# cslr_venc_001 register map
Vendor: Texas Instruments
Peripheral module from a debugger description file.
Registers are 32-bit, access per field, reset 0x0 unless marked. A register's access mark holds for its fields unless they carry their own. Offsets are as the file gives them; lines under a group give offsets from that group; [hi:lo] are bit positions; {n}, {i} and the like mark numbered series; 'fields as' and 'values as' point back to an identical list; <NAME> marks a mode.

## VENC — VPBE Video Encoder / Digital LCD Subsystem (spec version: 1.00.w.02b)
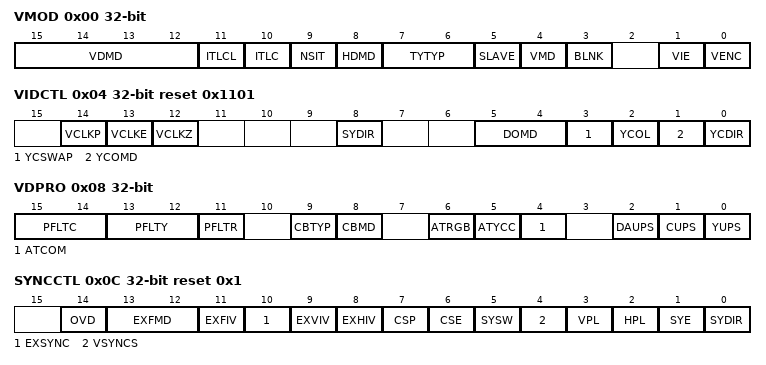
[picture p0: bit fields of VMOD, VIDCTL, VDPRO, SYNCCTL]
0x00 VMOD — Video Mode
  [15:12] VDMD rw — Digital video output mode
    0=YCBCR_16BIT (YCbCr parallel 16 bit); 1=YCBCR_8BIT (YCbCr serial 8 bit); 2=RGB666_18BIT (RGB666 parallel 18 bit); 3=RGB8_8BIT (RGB8 serial 8 bit); 4=EPSON; 5=CASIO; 6=UDISP_QVGA (uDISP (QVGA uDisplay)); 7=STN_LCD (STN (STN-LCD))
  [11] ITLCL rw — Non-interlace line number select Effective in standard SDTV non-interlace mode (VMD=0, HDMD=0, ITLC=1).
    0=262NTSC_312PAL (262 line (NTSC) / 312 line (PAL)); 1=263NTSC_313PAL (263 line (NTSC) / 313 line (PAL))
  [10] ITLC rw — Interlaced Scan Mode Enable Effective in standard SDTV mode (VMD=0, HDMD=0)
    0=INTERLACE; 1=NON_INTERLACE
  [9] NSIT rw — Nonstandard interlace mode Effective in non-standard mode (VMD=1).
    0=PROGRESSIVE; 1=INTERLACE
  [8] HDMD rw — HDTV mode Effective in standard mode (VMD=0).
    0=SDTV; 1=HDTV
  [7:6] TYTYP rw — TV Format Type Select Effective in standard mode (VMD=0). SDTV mode (HDMD=0) HDTV mode (HDMD=1)
    0=SDTV_NTSC (SDTV Mode - NTSC); 1=SDTV_PAL (SDTV Mode - PAL); 2=SDTV_RESERVEDS1 (SDTV Mode - reservedS1); 3=SDTV_RESERVEDS2 (SDTV Mode - reservedS2); 0=HDTV_525P (HDTV Mode - 525P); 1=HDTV_625P (HDTV Mode - 625P); 2=HDTV_RESERVEDH1 (HDTV Mode - reservedH1); 3=HDTV_RESERVEDH2 (HDTV Mode - reservedH2)
  [5] SLAVE rw — Master-slave select
    0=MASTERMODE; 1=SLAVEMODE
  [4] VMD rw — Video timing
    0=NTSC_PALTIMING; 1=NOTNTSC_PALTIMING
  [3] BLNK rw — Blanking enable Sync signal and color burst are still output
    0=NORMAL; 1=FORCEBLANKING
  [1] VIE rw — Composite Analog Output Enable
    0=FIXED_L_LEVEL_OUT (Fixed L level output); 1=NORMAL_COMPOSITE_OUT (Normal composite output)
  [0] VENC rw — Video Encoder Enable
    0=DISABLE; 1=ENABLE
0x04 VIDCTL reset 0x1101 — Video interface I/O control
  [14] VCLKP rw — VCLK output polarity
    0=NON_INVERSE; 1=INVERSE
  [13] VCLKE rw — VCLK output enable Note: Setting 1 outputs DCLK from VCLK pin. When 0 VCLKP setting is still available
    0=OFF; 1=ON
  [12] VCLKZ rw — VCLK pin output enable
    0=OUTPUT; 1=HIGHIMPEDENCE
  [8] SYDIR rw — Horizontal / Vertical Sync pin I/O control Set to 1 when external syncs are input Default is 1(input)
    0=OUTPUT; 1=INPUT
  [5:4] DOMD rw — Digital data output mode
    0=NORMAL_OUT (Normal output); 1=INVERSE_OUT (Inverse output); 2=L_LEVEL_OUT (L level output); 3=H_LEVEL_OUT (H level output)
  [3] YCSWAP rw — Swaps YOUT/COUT pins Interchanges the output data of YOUT and COUT
    0=NORMAL (Normal output); 1=SWAP_YC (Interchange YOUT and COUT)
  [2] YCOL rw — YOUT / COUT pin output level Setting DC out option will output the value in the YCOLVL register on YOUT/COUT pins. Effective only when YOUT/COUT pin is set as output (YCDIR=0).
    0=NORMAL_OUT (Normal output); 1=DCLEVEL_OUT (DC level output)
  [1] YCOMD rw — YOUT / COUT pin output mode Setting DV out will output the digital video output generated in video encoder on the YOUT/COUT pins. Setting Through Mode directly outputs the data from the YIN/CIN pins on the YOUT/COUT pins.
    0=DIGITAL_VIDEO_OUT (Digital video output); 1=YC_INPUT_PASSTHRU (YIN / CIN input through)
  [0] YCDIR rw — YOUT / COUT pin direction Note: YOUT/COUT pin is used as YC data input pin for CCDC. Set '0' for digital video output In Input Mode, YOUT/COUT pins are used as YC data input pins for CCDC. Set to Outptu Mode for digital video output. When UDISP digital video output mode is selected (VOMD=6), COUT[1:0] pins are always set to input.
    0=OUTPUT; 1=INPUT
0x08 VDPRO — Video data processing
  [15:14] PFLTC rw — C Prefilter select Note: When PFLTR and PFLTC are '1', use PFLTY to 1 to adjust delay between Y and C. When other combinations are selected, the delay is adjusted automatically on hardware.
    0=NOFILTER; 1=1_1; 2=1_2_1
  [13:12] PFLTY rw — Y Prefilter select Note: When PFLTR and PFLTY are '1', use PFLTC to 1 to adjust delay between Y and C. When other combinations are selected, the delay is adjusted automatically on hardware.
    0=NOFILTER; 1=1_1; 2=1_2_1
  [11] PFLTR rw — Prefilter sampling frequency
    0=ENCCLOCK_2; 1=ENCCLOCK
  [9] CBTYP rw — Color Bar Type
    0=75PCT; 1=100PCT
  [8] CBMD rw — Color bar mode
    0=NORMAL (Normal output); 1=COLORBAR (Color bar output)
  [6] ATRGB rw — Input video Attenuation control for RGB
    0=NOATTENUATION; 1=REC601_LVL (0-255 => REC601 specified level)
  [5] ATYCC rw — Input video Attenuation control for YCbCr
    values as ATRGB
  [4] ATCOM rw — Input video Attenuation control for composite
    values as ATRGB
  [2] DAUPS rw — DAC x2 up-sampling enable
    0=OFF; 1=ON
  [1] CUPS rw — C signal up-sampling enable
    0=OFF; 1=ON
  [0] YUPS rw — Y signal up-sampling enable
    0=OFF; 1=ON
0x0C SYNCCTL reset 0x1 — Sync control
  [14] OVD rw — OSD vsync delay
    0=NODELAY; 1=DELAY (Delay 0.5H)
  [13:12] EXFMD rw — External field detection mode Effective in slave operation (SLAVE=1).
    0=LATCH_EXT_FLD_AT_VDHIGH (latch ext. field at external VD rising edge); 1=USE_RAW_EXT_FLD (use raw external field); 2=USE_EXT_VSYNC_AS_FLDID (use external vsync as field ID); 3=DET_EXT_VSYNC_PH (detect external vsync phase)
  [11] EXFIV rw — External field input inversion Effective in slave operation (SLAVE=1). External field
    0=NON_INVERSE; 1=INVERSE
  [10] EXSYNC rw — External sync select
    0=HSYNC_VSYNCPIN; 1=CCDSYNCSIGNAL
  [9] EXVIV rw — External vertical sync input polarity
    0=ACTIVEH; 1=ACTIVEL
  [8] EXHIV rw — External horizontal sync input polarity
    0=ACTIVEH; 1=ACTIVEL
  [7] CSP rw — Composite signal output polarity Note: Specifies composite signal output polarity from COUT3 pin in YCC8 or RGB8 mode
    0=ACTIVEH; 1=ACTIVEL
  [6] CSE rw — Composite signal output enable Note: Specifies composite signal output polarity from COUT3 pin in YCC8 or RGB8 mode
    0=OFF; 1=ON
  [5] SYSW rw — Output sync select Note: Applicable to Standard mode only Setting '1' in standard mode outputs the pulse width processed by the SYNCPLS register as output sync signal.
    0=NORMAL; 1=SYNC_PW_PROC (Sync pulse width processing mode)
  [4] VSYNCS rw — Vertical sync output signal
    0=VSYNC (Vertical sync signal); 1=COMPOSITE_SYNC (composite sync signal)
  [3] VPL rw — Vertical sync output polarity
    0=ACTIVEH; 1=ACTIVEL
  [2] HPL rw — Horizontal sync output polarity
    0=ACTIVEH; 1=ACTIVEL
  [1] SYE rw — Vertical sync output enable The output comes to ON when this is set to 1, and the signal selected by the VSSW is output from VSYNC pin. Setting 0 outputs inactive level determined by VPL.
    0=OFF; 1=ON
  [0] SYDIR rw — Horizontal sync output enable The output comes to ON when this is set to 1, and the signal selected by the VSSW is output from HSYNC pin. Setting 0 outputs inactive level determined by HPL.
    0=OFF; 1=ON
0x10 HSPLS — Horizontal Sync pulse width
  [12:0] HSPLS rw — Horizontal sync pulse width (no of ENC clocks) Note: Effective in non-standard mode or sync processing mode (SYSW = 1)
0x14 VSPLS — Vertical Sync pulse width
  [12:0] VSPLS rw — Vertical sync pulse width (no of ENC clocks) Note: Effective in non-standard mode or sync processing mode (SYSW = 1)
0x18 HINT — Horizontal interval
  [12:0] HINT rw — Horizontal interval (no of ENC clocks) Note: Effective in non-standard mode, If OSD clock is (ENC clock / 2), Specify even values. Interval is HINT+1
0x1C HSTART — Horizontal valid data start position
  [12:0] HSTART rw — Horizontal valid data start position Note: Specify number of ENC clocks from start of horizontal sync. LCD_OE is asserted at the position specified here and the data output starts.
0x20 HVALID — Horizontal data valid range
  [12:0] HVALID rw — Horizontal data valid range Note: specify number of ENC clocks. LCD_OE is asserted during the period specified here and valid data is output. The data outside of valid range is output in L.
0x24 VINT — Vertical interval
  [12:0] VINT rw — Vertical interval (no of lines) Note: Effective in non-standard mode The interval is represented by VINT+1
0x28 VSTART — Vertical valid data start position
  [12:0] VSTART rw — Vertical valid data start position Note: Specify number of lines
0x2C VVALID — Vertical data valid range
  [12:0] VVALID rw — Vertical data valid range Note: specify number of lines
0x30 HSDLY — Horizontal sync delay
  [12:0] HSDLY rw — Output delay of horizontal sync signal Note: This will delay the HSYNC signal by ENC clock
0x34 VSDLY — Vertical sync delay
  [12:0] VSDLY rw — Output delay of vertical sync signal Note: This will delay the VSYNC signal by ENC clock
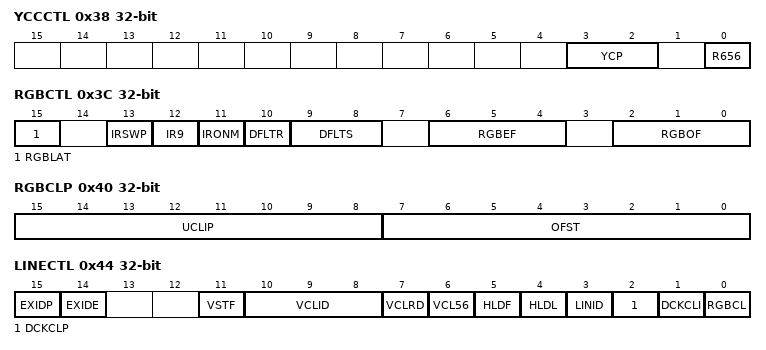
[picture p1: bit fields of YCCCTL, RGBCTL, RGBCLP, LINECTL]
0x38 YCCCTL — YCbCr control
  [3:2] YCP rw — YC output order Based on YCC mode
    0=YCC16_CBCR (YCC16 mode - CbCr); 1=yCC16_CRCB (YCC16 mode - CrCb); 0=YCC8_CB_Y_CR_Y (YCC8 mode - Cb-Y-Cr-Y); 1=YCC8_Y_CR_Y_CB (YCC8 mode - Y-Cr-Y-Cb); 2=YCC8_CR_Y_CB_Y (YCC8 mode - Cr-Y-Cb-Y); 3=YCC8_Y_CB_Y_CR (YCC8 mode - Y-Cb-Y-Cr)
  [0] R656 rw — REC656 mode This is ITU-R BT.656 format and is effective when the OSD clock runs at ENC clock/2.
    0=NORMAL; 1=REC656 (REC656 mode)
0x3C RGBCTL access not given (reset mask 0xFFFFFFF8) — RGB control
  [15] RGBLAT rw — RGB latch setting Set 1 to latch and output the data input in serial RGB output. This is set when data with the same pixel are output serially.
    0=NORMALOUTPUT; 1=LATCHMODE
  [13] IRSWP rw — Swap order of data output in IronMan mode Effective only IRONM=1
    0=NORMAL; 1=IR_SWAP (Data swap)
  [12] IR9 rw — IronMan 9bit mode Effective only IRONM=1. When 1, 24-bit RGB data (upper 6-bits of each color) is serially output on 9-bit data bus. The output format is the first is R[7:2] and G[7:5] and the second is G[4:2] and B[7:2]. This order can be swapped by IRSWP register.
    0=IR_8BIT (8-bit); 1=IR_9-BIT (9-bit)
  [11] IRONM rw — Iron-man type RGB output Effective in SRGB mode
    0=NORMAL; 1=IRONMAN (Iron-man type)
  [10] DFLTR rw — RGB LPF sampling frequency Effective in all digital output modes with RGB output Note: Effective in all digital modes with RGB output
    0=ENCCLOCK_2; 1=ENCCLOCK
  [9:8] DFLTS rw — RGB LPF select Note: Effective in all digital modes with RGB output
    0=NOFILTER; 1=1_2_1; 2=1_2_4_2_1
  [6:4] RGBEF rw — RGB output order (Line Id = 1) Note: Effective in RGB8, EPSON and CASIO modes. The line ID at RGBCL=1 represents the culling line ID set in the CULLLINE register. At RGBCL=0, it represents normal line ID.
    0=R0_G1_B2; 1=R0_B1_G2; 2=G0_R1_B2; 3=G0_B1_R2; 4=B0_R1_G2; 5=B0_G1_R2
  [2:0] RGBOF — RGB output order (Line Id = 0) Note: Effective in RGB8, EPSON and CASIO modes. The line ID at RGBCL=1 represents the culling line ID set in the CULLLINE register. At RGBCL=0, it represents normal line ID.
    values as RGBEF
0x40 RGBCLP — RGB level clipping
  [15:8] UCLIP rw — Upper clip level for RGB output Note: Effective in all digital output modes with RGB output. Clipping is done following offset addition
  [7:0] OFST rw — Offset level for RGB output Note: Effective in all digital output modes with RGB output. Offset specified here can be added to RGB converted from YCbCr
0x44 LINECTL — Line Id control
  [15] EXIDP rw — External Line Id signal polarity Effective at EXIDE=1
    0=NON_INVERSE; 1=INVERSE
  [14] EXIDE rw — External Line Id signal input mode Set External to perform the line control using external line ID signal, which can be input from a GIO. Otehrwise, the line ID is generated internally.
    0=INTERNALIDLINE; 1=EXTERNALIDLINE
  [11] VSTF rw — Vertical data valid start position field mode When 1, different start line can be specified for vertical data valid start position by VSTARTA register.
    0=NORMALMODE; 1=FIELDMODE
  [10:8] VCLID rw — Vertical Culling line position Specifies which line will be culled of every six lines. No culling will be applied when VCLID is greater than 5. This bit is effective when VCL56=1.
  [7] VCLRD rw — Vertical Culling counter reset mode When 0, the counter for vertical culling is reset to zero at vertical sync. When 1, it is reset to a random value at vertical sync. Effective when VCL56=1.
    0=RESET_0 (Reset to 0); 1=RESET_RAND (Reset to Random value)
  [6] VCL56 rw — Digital output vertical culling Enabling discards one line of video output every six lines. This can be used to output NTSC valid lines with PAL timing.
    0=NOCULLING; 1=5_6CULLING
  [5] HLDF rw — Digital output Field Hold Note: Effective in non-standard mode. Enabling suspends the video output when current field output is completed. Reading the data from OSD is suspended during this period and the output of sync signal and video data ar
    0=NORMAL; 1=OUTPUTHOLD
  [4] HLDL rw — Digital output Line Hold Note: Effective in non-standard mode. Enabling suspends the video output when current line output is completed. Reading the data from OSD is suspended during this period and the output of sync signal and video data are al
    0=NORMAL; 1=OUTPUTHOLD
  [3] LINID rw — Start line Id control in even field
    0=LINEID_0; 1=LINEID_1
  [2] DCKCLP rw — DCLK pattern switching by culling line Id When this is enabled, the DCLK pattern can be switched according to the culling line ID set by the CULLLINE register. The DCLK pattern on each line is specified by the DCLKPTN and DCLKPTNA registers.
    0=OFF; 1=ON
  [1] DCKCLI rw — DCLK polarity inversion by culling line Id When this is disabled, the DCLK polarity is fixed anytime as specified by the VCLKP register. Enabling inverts this polarity according to the culling line ID set by the CULLLINE register.
    0=OFF; 1=ON
  [0] RGBCL rw — RGB output order switching by culling line Id Disabling switches RGB output order every line. Enabling switches this order according to the XORed signal of the line ID and the culling line ID set by the CULLLINE register. The output order on each
    0=OFF; 1=ON
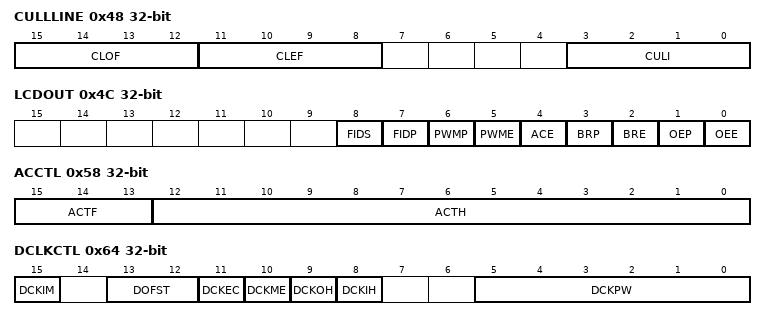
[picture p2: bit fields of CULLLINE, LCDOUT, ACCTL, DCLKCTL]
0x48 CULLLINE access not given — Culling line control
  [15:12] CLOF rw — Culling line Id toggle position (Odd field)
  [11:8] CLEF rw — Culling line Id toggle position (Even field)
  [3:0] CULI rw — Culling line Id inversion interval
0x4C LCDOUT — LCD output signal control
  [8] FIDS rw — GIO39 output signal select Note: Select GIO29 signal using FSEL2[11:10] = 01
    0=FIELDID; 1=LCD_OE
  [7] FIDP rw — Field Id output polarity
    0=NON_INVERSE; 1=INVERSE
  [6] PWMP rw — PWM output pulse polarity
    0=ACTIVEH; 1=ACTIVEL
  [5] PWME rw — PWM output control
    0=OFF; 1=ON
  [4] ACE rw — LCD_AC output control
    0=OFF; 1=ON
  [3] BRP rw — Bright output polarity
    0=NON_INVERSE; 1=INVERSE
  [2] BRE rw — Bright output control
    0=OFF; 1=ON
  [1] OEP rw — LCD_OE output polarity
    0=ACTIVEH; 1=ACTIVEL
  [0] OEE rw — LCD_OE output control
    0=OFF; 1=ON
0x50 BRTS — Brightness start position signal control
  [12:0] BRTS rw — Bright pulse start position Specify the number of ENC cycles from HSYNC signal.
0x54 BRTW — Brightness width signal control
  [12:0] BRTW rw — Bright pulse width Specify the number of ENC cycles.
0x58 ACCTL — LCD_AC signal control
  [15:13] ACTF rw — LCD_AC toggle interval Note: LCD_AC is toggled every field specified here
  [12:0] ACTH rw — LCD_AC toggle horizontal position Note: LCD_AC is toggled by the number of ENC clocks from the rising edge of horizontal sync signal
0x5C PWMP — PWM start position signal control
  [12:0] PWMP rw — PWM output period Specify the number of ENC clocks. Period is PWMP + 1
0x60 PWMW — PWM width signal control
  [12:0] PWMW rw — PWM output pulse width Specify the H pulse width by ENC clock. Setting '0' makes PWM output L level always, Setting bigger value than PWMP sets to H level always,
0x64 DCLKCTL — DCLK control
  [15] DCKIM rw — DCLK Internal Mode When enabled, a different pattern can be specified for internal DCLK from output DCLK. In this mode, DCLKPTN0A-PCLKPTN3A and DCLKHSTTA are used to specify the internal DCLK pattern and its pattern valid bit width respectively. Th
    0=OFF; 1=ON
  [13:12] DOFST rw — DCLK output offset To adjust the DCLK delay output from VCLK pin by ENC clock. When DCLK output is configured as ENC clock gating with DCKEC=1 and DCKOH=0, these bits have no meaning.
    0=ZERO (0); 1=MINUS_HALF (-0.5); 2=PLUS_HALF (0.5); 3=PLUS_ONE (1)
  [11] DCKEC rw — DCLK Pattern mode When 0, the specified value in DCLKPTN (or DCLKPTNA) register becomes the clock level of DCLK. When 1, DCLKPTN works as the clock enable for ENC clock.
    0=LEVEL; 1=ENABLE
  [10] DCKME rw — DCLK mask control Masks are specified by the DCLKHSTT, DCLKHVLD, DCLKVSTT and DCLKVVLD registers. Enabling represents the mask is ON and outputs the clock in specified valid area. Disabling represents the mask is OFF and outputs directly the DCLK
    0=OFF; 1=ON
  [9] DCKOH rw — DCLK output divide Enabling divides the clock by two and outputs it from VCLK pin. RGB data is output by the rising of internal DCLK and only divided clock output is output. Thus, this can be used to connect to the LCD that captures the data usin
    0=DIV_BY_1 (Divide by 1); 1=DIV_BY_2 (Divide by 2)
  [8] DCKIH rw — Internal DCLK output divide Enabling divides internal DCLK clock by two. When the clock output is divided by 1 (DCKOH=0), two clocks can be output per one data. Thus, this can be used to connect to the LCD that requires double clock frequency of d
    0=DIV_BY_1 (Divide by 1); 1=DIV_BY_2 (Divide by 2)
  [5:0] DCKPW rw — DCLK pattern valid bit width Note: Set the width of valid bits aming 64 bits in the DCLKPTN0-3 registers
{0x68+4i} DCLKPTN{i} (i=0..3) — DCLK pattern {i}
  [15:0] DCPTN{i} rw — DCLK pattern The specified bit pattern is output in resolution of ENC clock units
{0x78+4i} DCLKPTN{i}A (i=0..3) — DCLK auxiliary pattern {i}
  [15:0] DCPTN{i}A rw — DCLK pattern (auxiliary) The specified bit pattern is output in resolution of ENC clock units
0x88 DCLKHS — Horizontal DCLK mask start
  [12:0] DCHS rw — Horizontal DCLK mask start position This is specified in number of ENC clocks from start of the horizontal sync signal
0x8C DCLKHSA — Horizontal auxiliary DCLK mask start
  [12:0] DCHS rw — Horizontal DCLK (auxiliary) mask start position This is specified in number of ENC clocks from start of the horizontal sync signal
0x90 DCLKHR — Horizontal DCLK mask range
  [12:0] DCHR rw — Horizontal DCLK mask range This is specified in ENC clocks
0x94 DCLKVS — Vertical DCLK mask start
  [12:0] DCVS rw — DCLK vertival mask start position This is specified in lines from vertical sync signal
0x98 DCLKVR — Vertical DCLK mask range
  [12:0] DCVR rw — DCLK vertical mask range This is specified in number of lines
0x9C ATR0 — Video Attribute Data #0
  [7:0] ATR0 rw — Video attribute data register 0 NTSC - Set the WORD0 data. - Bit7-6 is unused, - Bit5-3 is WORD0-B, - Bit2-0 is WORD0-A PAL - not used
0xA0 ATR1 — Video Attribute Data #1
  [7:0] ATR1 rw — Video attribute data register 1 NTSC - Set the WORD1 and WORD2 data - Bit7-4 is WORD2, - Bit3-0 is WORD1 PAL - Set the GROUP1 and GROUP2 data. - Bit7-4 is GROUP2, - Bit3-0 is GROUP1
0xA4 ATR2 — Video Attribute Data #2
  [7:0] ATR2 rw — Video attribute data register 2 NTSC - Set CRC data and enable attribute insertion. - Bit7 is ATR_EN, - Bit6 is unused, - Bit5-0 is CRC PAL - Set GROUP3 and GROU4 data and enable attribute insertion. - Bit7 is ATR_EN, - Bit6 is ununsed, - Bit5-3 is GROUP4 and - Bit2-0 is GROUP3 ATR_EN: Attribute data insertion enable 0: No insertion 1: Insertion
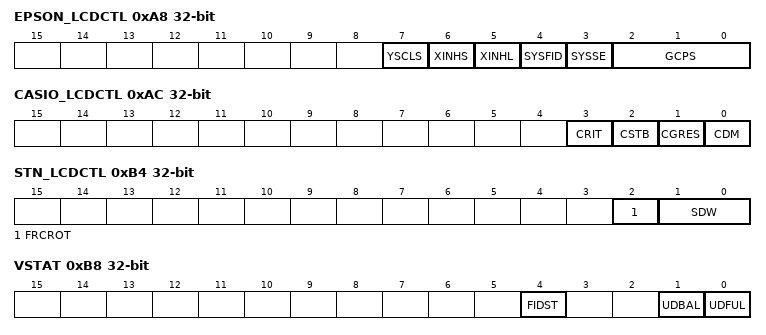
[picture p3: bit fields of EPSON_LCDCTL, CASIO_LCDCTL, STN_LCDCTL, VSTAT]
0xA8 EPSON_LCDCTL — EPSON LCD Control
  [7] YSCLS rw — Low pulse number of YSCL
    0=1PULSE (one pulse (1/2 reset drive)); 1=2PULSES (two pulses (1/2 select drive))
  [6] XINHS rw — XINH Signal select
    0=DCOUTPUT; 1=TGCONTROLLED
  [5] XINHL rw — XINH DC level
    0=LLEVELOUT (L level output); 1=HLEVELOUT (H level output)
  [4] SYSFID rw — SYS function applied field ID select
  [3] SYSSE rw — SYS function enable Note: setting '1 resets the vertical counter one line earlier in the field selected by SYSFID
    0=OFF; 1=ON
  [2:0] GCPS rw — GCP pattern select Note: When RAM is used, data written in RAM address 0-63 is shifter out by one bit from MSB to LSB and output as GCP pulse
    {v}=ROM_TYPE{v} (v=0..3); 4=RAM
0xAC CASIO_LCDCTL — CASIO LCD Control
  [3] CRIT rw — RIT port control Note: Setting is enabled at the rising edge of horizontal sync signal
    0=LLEVELOUT (L level output); 1=HLEVELOUT (H level output)
  [2] CSTB rw — STBYB port control Note: CP output is fixed at H level when 0
    0=LLEVELOUT (L level output); 1=HLEVELOUT (H level output)
  [1] CGRES rw — GRES port control
    0=NORMAL; 1=FIXEDLLEVEL
  [0] CDM rw — Display mode
    0=NORMAL; 1=VERTICALREVERSEMODE
0xB0 UDISP_LCDCTL — uDisplay LCD control
  [7:0] FSW rw — Frame start pulse width This is Specified in ENC clocks
0xB4 STN_LCDCTL — STN LCD control
  [2] FRCROT rw — FRC table rotation enable When enabled, the FRC table for each color is automatically rotated when each pixel data is latched. This can be useful to equalize dot blinking pattern.
    0=DISABLE; 1=ENABLE
  [1:0] SDW rw — STN-LCD data bus width
    0=8BITS; 1=4BITS; 2=12BITS
0xB8 VSTAT — Video status
  [4] FIDST rw — Field ID monitor
  [1] UDBAL rw — uDisplay 'Balance signal' monitor
  [0] UDFUL rw — uDisplay 'Full' signal monitor
0xBC RAMADR — GCP/FRC table RAM address
  [5:0] RAMADR rw — GCP/FRC table RAM address.
0xC0 RAMPORT — GCP/FRC table RAM data port
  [15:0] RAMPORT rw — RAM data port Note: While reading, the data in the address specified in the RAMADR register can be read. While writing, the data is written to the address specified in the RAMADR register. The RAMADR is automatically incremented every access to the RAMP register in both write and read cases.
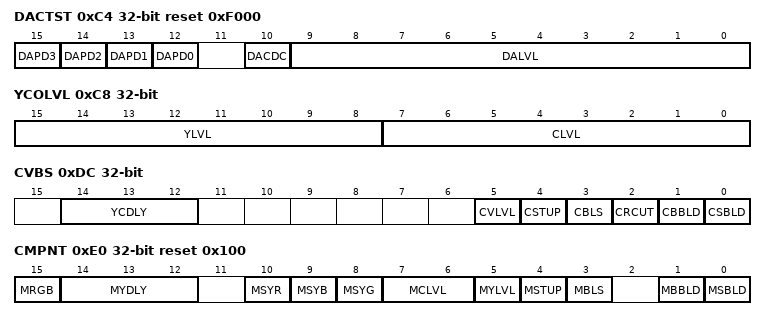
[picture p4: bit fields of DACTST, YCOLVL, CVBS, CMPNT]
0xC4 DACTST reset 0xF000 — DAC Test
  [n+12] DAPD{n} rw (n=0..3) — DAC{n} power-down
    0=NORMAL (Normal mode); 1=PWRDN (Power-down mode)
  [10] DACDC rw — DAC DC output mode Note: Enabling converts the value written in the DALVL register to DAC and directly outputs from DAOUT
    0=NORMAL; 1=DCOUT (DC output mode)
  [9:0] DALVL rw — DC level control
0xC8 YCOLVL — YOUT and COUT levels
  [15:8] YLVL rw — YOUT DC level
  [7:0] CLVL rw — COUT DC level
0xCC SCPROG reset 0x132 — Sub-carrier programming
  [9:0] SCSD rw — Sub-carrier initial phase value Phase in degrees specified by SCSD/1024*360
{0xCC+4i} RSV{i} ro (i=1..3) — Reserved
0xDC CVBS — Composite Mode
  [14:12] YCDLY rw — Delay adjsutment of Y signal in composite signal Note: The value represented is 2's complement
    0=0; 1=PLUS_1 (1); 2=PLUS_2 (2); 3=PLUS_3 (3); 4=MINUS_4 (-4); 5=MINUS_3 (-3); 6=MINUS_2 (-2); 7=MINUS_1 (-1)
  [5] CVLVL rw — Composite video level (sync/white)
    0=286MV_714MV; 1=300MV_700MV
  [4] CSTUP rw — Setup level at NTSC output
    0=0_PCT; 1=7P5_PCT (7.5%)
  [3] CBLS rw — Blanking shape disable
    0=ENABLE; 1=DISABLE
  [2] CRCUT rw — Chroma signal low pass filter select
    0=1P5MHZ_CUT0FF (1.5 MHz cut-0ff); 1=3MHZ_CUTOFF
  [1] CBBLD rw — Blanking build up time for composite output
    0=140US; 1=300US
  [0] CSBLD rw — Sync build up time for composite output
    0=140US; 1=200US
0xE0 CMPNT reset 0x100 — Component Mode
  [15] MRGB rw — RGB Mode select for component output
    0=YPBPR; 1=RGB
  [14:12] MYDLY rw — Delay adjsutment of Y signal in component mode Note: The value represented is 2's complement
    values as CVBS.YCDLY
  [10] MSYR rw — Sync on Pr (or R)
    0=NOSYNC; 1=SYNCON
  [9] MSYB rw — Sync on Pb (or B)
    0=NOSYNC; 1=SYNCON
  [8] MSYG rw — Sync on Y (or G)
    0=NOSYNC; 1=SYNCON
  [7:6] MCLVL rw — Chroma level for component YPbPr
    0=350MV_SMPTEN10; 1=467MV_BETACAM; 2=324MV_MII
  [5] MYLVL rw — Luma level (sync/white) for component YPbPr
    0=286MV_714MV; 1=300MV_700MV
  [4] MSTUP rw — Setup for component YPbPr
    0=0_PCT; 1=7P5_PCT (7.5%)
  [3] MBLS rw — Blanking shape disable When 1, blanking shaping feature is disabled.
    0=ENABLE; 1=DISABLE
  [1] MBBLD rw — Blanking build up time for component output (interlace)
    0=140US; 1=300US; 0=70US; 1=150US
  [0] MSBLD rw — Sync build up time for component output (interlace) (interlace)
    0=140US; 1=200US; 0=70US; 1=100US
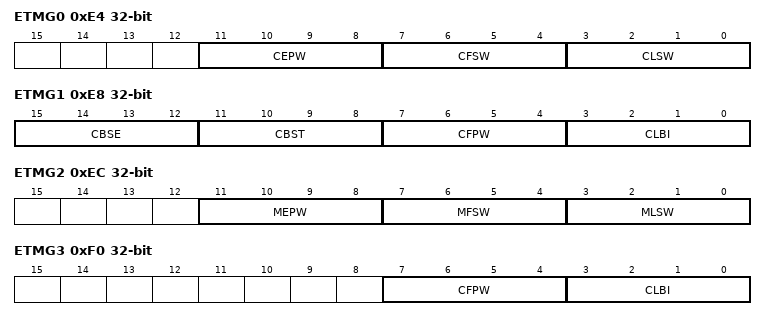
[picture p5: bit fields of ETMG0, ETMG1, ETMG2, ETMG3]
0xE4 ETMG0 — CVBS timing control 0
  [11:8] CEPW rw — Equalizing pulse width offset for composite output This is set by ENC clock. This register is represented as signed-integer (2's complement).
  [7:4] CFSW rw — Field sync pulse width offset for composite output This is set by ENC clock. This register is represented as signed-integer (2's complement).
  [3:0] CLSW rw — Line sync pulse width offset for composite output This is set by ENC clock. This register is represented as signed-integer (2's complement).
0xE8 ETMG1 — CVBS timing control 1
  [15:12] CBSE rw — Burst end position offset for composite output This is set by ENC clock. This register is represented as signed-integer (2's complement).
  [11:8] CBST rw — Burst start position offset for composite output This is set by ENC clock. This register is represented as signed-integer (2's complement).
  [7:4] CFPW rw — Front porch position offset for composite output This is set by ENC clock. This register is represented as signed-integer (2's complement).
  [3:0] CLBI rw — Line blanking end position offset for composite output This is set by ENC clock. This register is represented as signed-integer (2's complement).
0xEC ETMG2 — Component timing control 0
  [11:8] MEPW rw — Equalizing pulse width offset for component output This is set by ENC clock. This register is represented as signed-integer (2's complement).
  [7:4] MFSW rw — Field sync pulse width offset for component output This is set by ENC clock. This register is represented as signed-integer (2's complement).
  [3:0] MLSW rw — Line sync pulse width offset for component output This is set by ENC clock. This register is represented as signed-integer (2's complement).
0xF0 ETMG3 — Component timing control 1
  [7:4] CFPW rw — Front porch position offset for component output This is set by ENC clock. This register is represented as signed-integer (2's complement).
  [3:0] CLBI rw — Line blanking end position offset for component output This is set by ENC clock. This register is represented as signed-integer (2's complement).
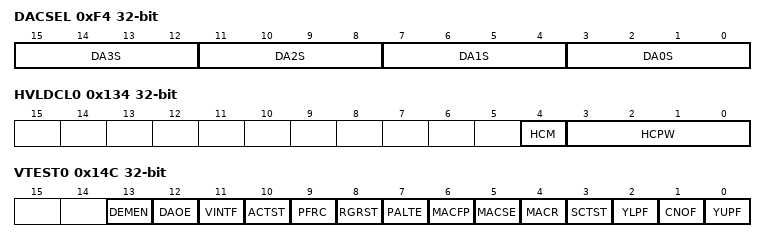
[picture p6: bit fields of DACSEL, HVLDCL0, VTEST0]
0xF4 DACSEL access not given (reset mask 0xFFFFFF00) — DAC output select
  [all] fields
    0=CVBS; 1=SVIDEO_Y; 2=SVIDEO_C; 3=Y_G; 4=PB_B; 5=PR_R
  [15:12] DA3S rw — DAC3 output select
  [11:8] DA2S rw — DAC2 output select
  [7:4] DA1S — DAC1 output select
  [3:0] DA0S — DAC0 output select
0xF8 RSV4 ro — reserved
  [31:0] RSV4 — Reserved
0xFC RSV5 ro — reserved
  [31:0] RSV5 — Reserved
0x100 ARGBX0 reset 0x200 — Analog RGB Matrix 0
  [10:0] AGY rw — YCbCr->RGB matrix coefficient GY for analog RGB out Equation: | R | | GY 0 RV | | Y-16 | | G | = 1/512 | GY -GU -GV | | Cb-128 | | B | | GY BU 0 | | Cr-128 | Default: | R | | 512 0 702 | | Y-16 | | G | = 1/512 | 512 -172 -357 | | Cb-128 | | B | | 512 887 0 | | Cr-128 |
0x104 ARGBX1 reset 0x2BE — Analog RGB Matrix 1
  [10:0] ARV rw — YCbCr->RGB matrix coefficient RV for analog RGB out Equation: | R | | GY 0 RV | | Y-16 | | G | = 1/512 | GY -GU -GV | | Cb-128 | | B | | GY BU 0 | | Cr-128 | Default: | R | | 512 0 702 | | Y-16 | | G | = 1/512 | 512 -172 -357 | | Cb-128 | | B | | 512 887 0 | | Cr-128 |
0x108 ARGBX2 reset 0xAC — Analog RGB Matrix 2
  [10:0] AGU rw — YCbCr->RGB matrix coefficient GU for analog RGB out Equation: | R | | GY 0 RV | | Y-16 | | G | = 1/512 | GY -GU -GV | | Cb-128 | | B | | GY BU 0 | | Cr-128 | Default: | R | | 512 0 702 | | Y-16 | | G | = 1/512 | 512 -172 -357 | | Cb-128 | | B | | 512 887 0 | | Cr-128 |
0x10C ARGBX3 reset 0x165 — Analog RGB Matrix 3
  [10:0] AGV rw — YCbCr->RGB matrix coefficient GV for analog RGB out Equation: | R | | GY 0 RV | | Y-16 | | G | = 1/512 | GY -GU -GV | | Cb-128 | | B | | GY BU 0 | | Cr-128 | Default: | R | | 512 0 702 | | Y-16 | | G | = 1/512 | 512 -172 -357 | | Cb-128 | | B | | 512 887 0 | | Cr-128 |
0x110 ARGBX4 reset 0x377 — Analog RGB Matrix 4
  [10:0] ABU rw — YCbCr->RGB matrix coefficient BU for analog RGB out Equation: | R | | GY 0 RV | | Y-16 | | G | = 1/512 | GY -GU -GV | | Cb-128 | | B | | GY BU 0 | | Cr-128 | Default: | R | | 512 0 702 | | Y-16 | | G | = 1/512 | 512 -172 -357 | | Cb-128 | | B | | 512 887 0 | | Cr-128 |
0x114 DRGBX0 reset 0x200 — Digital RGB Matrix 0
  [10:0] DGY rw — YCbCr->RGB matrix coefficient GY for Digital RGB out Equation: | R | | GY 0 RV | | Y-16 | | G | = 1/512 | GY -GU -GV | | Cb-128 | | B | | GY BU 0 | | Cr-128 | Default: | R | | 512 0 702 | | Y-16 | | G | = 1/512 | 512 -172 -357 | | Cb-128 | | B | | 512 887 0 | | Cr-128 |
0x118 DRGBX1 reset 0x2BE — Digital RGB Matrix 1
  [10:0] DRV rw — YCbCr->RGB matrix coefficient RV for Digital RGB out Equation: | R | | GY 0 RV | | Y-16 | | G | = 1/512 | GY -GU -GV | | Cb-128 | | B | | GY BU 0 | | Cr-128 | Default: | R | | 512 0 702 | | Y-16 | | G | = 1/512 | 512 -172 -357 | | Cb-128 | | B | | 512 887 0 | | Cr-128 |
0x11C DRGBX2 reset 0xAC — Digital RGB Matrix 2
  [10:0] DGU rw — YCbCr->RGB matrix coefficient GU for Digital RGB out Equation: | R | | GY 0 RV | | Y-16 | | G | = 1/512 | GY -GU -GV | | Cb-128 | | B | | GY BU 0 | | Cr-128 | Default: | R | | 512 0 702 | | Y-16 | | G | = 1/512 | 512 -172 -357 | | Cb-128 | | B | | 512 887 0 | | Cr-128 |
0x120 DRGBX3 reset 0x165 — Digital RGB Matrix 3
  [10:0] DGV rw — YCbCr->RGB matrix coefficient GV for Digital RGB out Equation: | R | | GY 0 RV | | Y-16 | | G | = 1/512 | GY -GU -GV | | Cb-128 | | B | | GY BU 0 | | Cr-128 | Default: | R | | 512 0 702 | | Y-16 | | G | = 1/512 | 512 -172 -357 | | Cb-128 | | B | | 512 887 0 | | Cr-128 |
0x124 DRGBX4 reset 0x377 — Digital RGB Matrix 4
  [10:0] DBU rw — YCbCr->RGB matrix coefficient BU for Digital RGB out Equation: | R | | GY 0 RV | | Y-16 | | G | = 1/512 | GY -GU -GV | | Cb-128 | | B | | GY BU 0 | | Cr-128 | Default: | R | | 512 0 702 | | Y-16 | | G | = 1/512 | 512 -172 -357 | | Cb-128 | | B | | 512 887 0 | | Cr-128 |
0x128 VSTARTA — Vertical data valid start position for even field
  [12:0] DBU rw — Vertical data valid start position for even field Specify the number of lines
0x12C OSDCLK0 — OSD clock control 0
  [3:0] OCPW rw — OSD clock pattern bit width Sets the width of valid bit among all 16 bits in the OSDCLK1 register. The number of the valid bits is counted from LSB side to MSB side of the OSDCLK1.
0x130 OSDCLK1 reset 0x2 — OSD clock control 1
  [15:0] OCPT rw — OSD clock pattern
0x134 HVLDCL0 — Horizontal valid culling control 0
  [4] HCM rw — Horizontal valid culling mode When enabled, the LCD_OE signal is gated by the pattern specified by HCPT register.
    0=NORMAL_MODE; 1=HORIZ_VALID_CULL_MODE (Horizontal valid culling mode)
  [3:0] HCPW rw — Horizontal valid culling pattern bit width Set the width of valid bit among all 16 bits in the HVLDCL1 register. The number of the valid bits is counted from LSB side to MSB side of the HVLDCL1.
0x138 HVLDCL1 reset 0x2 — Horizontal valid culling control 1
  [15:0] HCPT rw — Horizontal culling pattern
0x13C OSDHADV — OSD horizontal sync advance
  [7:0] OHAD rw — OSD horizontal sync advance OSD horizontal sync assertion timing can be advanced by this register. By default, the timing is adjusted so that OSD timing related registers and VENC timing related registers are aligned. Specify the number of ENC cloc
0x140 SCTEST0 access not given reset 0x87 — Subcarrier frequency control 0 (INTERNAL USE ONLY)
  [7:0] SRATE rw — Sub-carrier frequency parameter 0 See VTEST0 register for equation
0x144 SCTEST1 access not given reset 0xFFE7 — Subcarrier frequency control 1 (INTERNAL USE ONLY)
  [15:0] SCCN rw — Sub-carrier frequency parameter 1 See VTEST0 register for equation (2s complement within 16-bit field, default is -25)
0x148 SCTEST2 access not given reset 0x8 — Subcarrier frequency control 2 (INTERNAL USE ONLY)
  [15:0] SCCP rw — Sub-carrier frequency parameter 2 See VTEST0 register for equation
0x14C VTEST0 access not given — Video Test 0 (INTERNAL USE ONLY)
  [13] DEMEN rw — DAC cell DEMEN control
  [12] DAOE rw — DAC cell Output Enable (OE) control
    0=NORMAL; 1=DAC_LOW_OUTPUT (DAOUT L level output)
  [11] VINTF rw — Interrupt factor
    0=V_SYNC (Vertical sync); 1=H_SYNC (Horizontal sync)
  [10] ACTST rw — VENC AC test mode For device testing
  [9] PFRC wo — FRC table preset Setting '1' presets the FRC table to 0-15 addresses in RAM. As preset value, that of LCD controller 'ML87V3104' manufactured by OKI is applied. Writing '0' performs no function. At reading, '0' is read all the time.
  [8] RGRST wo — VENC register set Setting '1' resets the VENC register to default setting. Writing '0' performs no function. At reading, '0' is read all the time.
  [7] PALTE rw — Timing at PAL signal output
    0=EVENFLD (Even field); 1=ODDFLD (Odd field)
  [6] MACFP rw — Field ID inversion for Macrovision circuit
    0=NON_INVERSION; 1=INVERSION
  [5] MACSE rw — Macrovision Y signal step output function enable This is ON by default
    0=ON; 1=OFF
  [4] MACR wo — Macrovision register reset Setting '1' resets the Macrovision register to default setting depending on current NTSC/PAL mode. Writing '0' performs no function. At reading, '0' is read all the time.
  [3] SCTST rw — Sub-carrier phase reset - Writing 1 resets the sub-carrier phase - Writing 0 has no function - Always 0 when read Sub-carrier frequency can be derived by SRATE?SCCN and SCCP registers by the following: f_sc = 1/1024 x (SRATE - SCCN/(SCCP-SCCN)) x 27MHz
  [2] YLPF rw — Y LPF Enable To apply 1+2+1 filter to Y signal in 13.5MHz sampling rate. (For test for DSC25-compatible)
    0=OFF; 1=ON
  [1] CNOF rw — Chroma LPF OFF
    0=ON; 1=OFF
  [0] YUPF rw — Luma upsampling filter select
    0=SINC ([3 0 m10 0 39 64 39 0 m10 0 3]); 1=TRI ([1 2 1])
0x150 VTEST1 access not given reset not defined — Video Test 1 (INTERNAL USE ONLY)
  [31:0] VTEST1 — Reserved
0x154 VTEST2 access not given reset not defined — Video Test 2 (INTERNAL USE ONLY)
  [31:0] VTEST2 — Reserved
